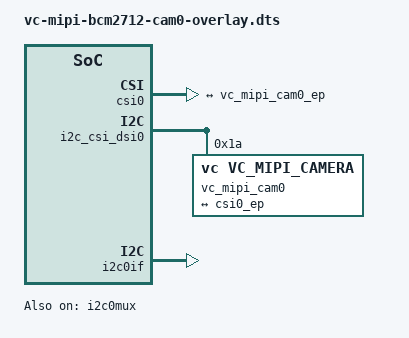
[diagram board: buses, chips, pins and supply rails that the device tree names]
//
// Definitions for cam 0 for RaspberryPi 5
//
// Copyright (C) 2024 - Florian Schmid, Vision Components GmbH
//




/dts-v1/;
/plugin/;

/ {
	fragment@0 {
		target = <&csi0>;
		__overlay__ {
			status = "okay";

			port {
				csi0_ep: endpoint {
					remote-endpoint = <&vc_mipi_cam0_ep>;
					data-lanes = <1 2 3 4>;
				};
			};
		};
	};
	fragment@1 {
		target = <&i2c_csi_dsi0>;
		__overlay__ {
			status = "okay";

			#address-cells = <1>;
			#size-cells = <0>;

			vc_mipi_cam0: camera0 {
				compatible = "vc,vc_mipi_camera";
				reg = <0x1a>;
				status = "okay";				
				port {
					vc_mipi_cam0_ep: endpoint {
						remote-endpoint = <&csi0_ep>;
						data-lanes = <1 2 3 4>;

					};
				};
			};
		};
	};
	fragment@2 {
		target = <&i2c0mux>;
		__overlay__ {
			status = "okay";

		};
	};
	fragment@3 {
		target = <&i2c0if>;
		__overlay__ {
			status = "okay";

		};
	};
	fragment@4 {
    	target = <&cam0_reg>;
    	__overlay__ {
       		status = "disabled";
    	};
	};
	fragment@5 {
		target = <&rp1_gpio>;
		__overlay__ {
			cam0_trigger_gpio: cam0_trigger_gpio {
				function = "gpio";
				pins = "gpio34";
				drive-strength = <0x0c>;   /* optional */
				bias-disable;              /* no pull */
				/* slew-rate = <0x01>; */  /* optional */
			};
		};
	};
	fragment@1001 {
		target = <&i2c_csi_dsi0>;
		__dormant__ {
			camera0 {
				port {
						endpoint {
							data-lanes = <1>;
						};
					};
				};
		};
	};
	fragment@1002 {
		target = <&i2c_csi_dsi0>;
		__dormant__ {
			camera0 {
				port {
						endpoint {
							data-lanes = <1 2>;

						};
					};
				};
		};
	};
	fragment@1004 {
		target = <&i2c_csi_dsi0>;
		__dormant__ {
			camera0 {
				port {
						endpoint {
							data-lanes = <1 2 3 4>;

						};
					};
				};
		};
	};
	fragment@2001 {
		target = <&csi0>;
		__dormant__ {
			status = "okay";
			port {
				endpoint {
					data-lanes = <1>;

				};
			};
		};
	};
	fragment@2002 {
		target = <&csi0>;
		__dormant__ {
			status = "okay";
			port {
				endpoint {
					data-lanes = <1 2>;

				};
			};
		};
	};
	fragment@2004 {
		target = <&csi0>;
		__dormant__ {
			status = "okay";
			port {
				endpoint {
					data-lanes = <1 2 3 4>;

				};
			};
		};
	};



	__overrides__ {
        cam0_lanes1 	   	=      <0>,"=1001=2001";
		cam0_lanes2 	   	=      <0>,"=1002=2002";
		cam0_lanes4 	   	=      <0>,"=1004=2004";		
		cam0_lanes0 	   	= 	   <0>,"-0-1";
		cam0_manu_ov	   	=      <&vc_mipi_cam0>,"reg:0=",<0x60>;
		cam0_manu_os	   	=      <&vc_mipi_cam0>,"reg:0=",<0x36>;

		cam0_libcamera_on	=      <&vc_mipi_cam0>,"libcamera";
		cam0_force_color	=      <&vc_mipi_cam0>,"force-color-mode";


    };
};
